# S1C31W74 register map
Vendor: Epson; Series: S1C31W74; File version: 1.11
CPU: CM0PLUS r0p1, little endian, MPU, no FPU, VTOR, 2 interrupt priority bits
Registers are 16-bit, read-write, reset 0x0 unless marked. A register's access mark holds for its fields unless they carry their own. Offsets are from the block's base; [hi:lo] are bit positions; {n}, {i} and the like mark numbered series; 'fields as' and 'values as' point back to an identical list.

## T16B_0 — 16-bit PWM timer channel 0 comparator/capture control
Base 0x40000400
Same registers: T16B_1 0x40000440
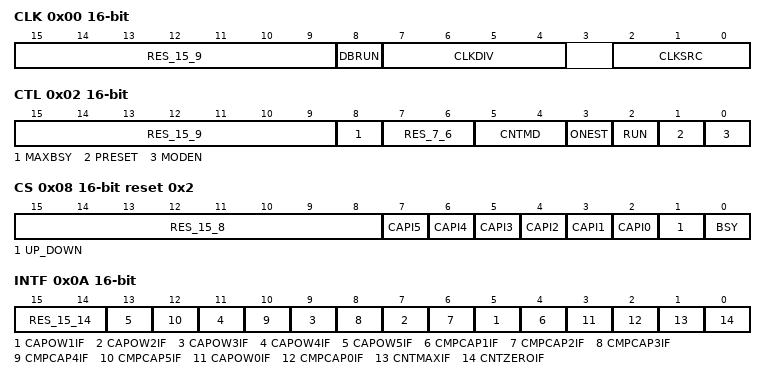
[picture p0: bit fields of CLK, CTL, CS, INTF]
0x00 CLK — Clock Control Register
  [15:9] RES_15_9 ro — Reserved bits
  [8] DBRUN — Enable clock on debug mode
    0=DISABLE; 1=ENABLE
  [7:4] CLKDIV — Clock division select
  [2:0] CLKSRC — Clock source select
    0=IOSC; 1=OSC1; 2=OSC3; 3=EXOSC; 4=EXCLN0; 5=EXCLN1; 6=EXCLN0_INV (EXCLn0 Invert); 7=EXCLN1_INV (EXCLn1 Invert)
0x02 CTL — Counter Control Register
  [15:9] RES_15_9 ro — Reserved bits
  [8] MAXBSY — Max register busy flag
    0=IDLE (Idle (can be written)); 1=BUSY (Busy status (cannot be written))
  [7:6] RES_7_6 ro — Reserved bits
  [5:4] CNTMD — Count mode select
    0=UP (Up count mode); 1=DOWN (Down count mode); 2=UP_DOWN (Up/down count mode)
  [3] ONEST — One shot mode
    0=REPEAT (Repeat mode); 1=ONESHOT (One-shot mode)
  [2] RUN — Count mode select
    0=STOP (Repeat mode); 1=RUN (One-shot mode)
  [1] PRESET write-1-sets — Counter preset (reset)
    on write: 0=NON (No effect); 1=ISSUE (Issue a preset (reset)) | on read: 0=COMPLETED (Resetting finished or normal operation); 1=IN_PROGRESS (Resetting in progress)
  [0] MODEN — T16B enable
    0=DISABLE (Disable (Stop supplying operating clock)); 1=ENABLE (Enable (Start supplying operating clock))
0x04 MC reset 0xFFFF — MAX Counter Data Register
  [15:0] MC — Max Counter Value
0x06 TC ro — Timer Counter Data Register
  [15:0] TC — Counter data
0x08 CS ro reset 0x2 — Counter Status Register
  [15:8] RES_15_8 — Reserved bits
  [7] CAPI5 — Capture5 input status
    0=LOW (Input signal = Low level); 1=HIGH (Input signal = High level)
  [6] CAPI4 — Capture1 input status
    values as CAPI5
  [n+2] CAPI{n} (n=0..3) — Capture{n} input status
    values as CAPI5
  [1] UP_DOWN — Counter UP/DOWN status
    0=DOWN (Count down); 1=UP (Count up)
  [0] BSY — Counter Run Status
    0=STOP (Idle); 1=RUN (Running)
0x0A INTF — Compare/Capture Interrupt Flag Register
  [15:14] RES_15_14 ro — Reserved bits
  [2n+3] CAPOW{n}IF ro write-1-clears (n=1..5) — Capture over write interrupt flag 1
    0=NOT_OCCURED (No cause of interrupt occurred); 1=OCCURED (Cause of interrupt occurred)
  [2n+2] CMPCAP{n}IF ro write-1-clears (n=1..5) — Compare/Capture interrupt flag 1
    values as CAPOW1IF
  [3] CAPOW0IF ro write-1-clears — Capture over write interrupt flag 0
    values as CAPOW1IF
  [2] CMPCAP0IF ro write-1-clears — Compare/Capture interrupt flag 0
    values as CAPOW1IF
  [1] CNTMAXIF ro write-1-clears — Counter Max interrupt flag
    values as CAPOW1IF
  [0] CNTZEROIF ro write-1-clears — Counter 0 interrupt flag
    values as CAPOW1IF
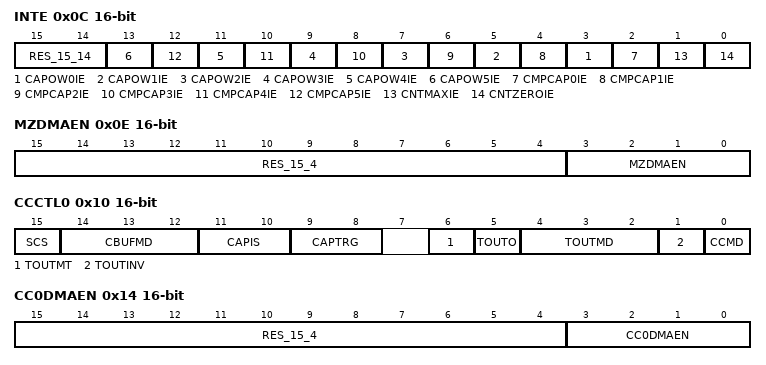
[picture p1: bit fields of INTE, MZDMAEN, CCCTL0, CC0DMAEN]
0x0C INTE — T16B Interrupt Enable Register
  [15:14] RES_15_14 ro — Reserved bits
  [2n+3] CAPOW{n}IE (n=0..5) — Capture over write interrupt enable {n}
    0=DISABLE; 1=ENABLE
  [2n+2] CMPCAP{n}IE (n=0..5) — Compare/Capture interrupt enable {n}
    0=DISABLE; 1=ENABLE
  [1] CNTMAXIE — Counter Max interrupt enable
    0=DISABLE; 1=ENABLE
  [0] CNTZEROIE — Counter 0 interrupt enable
    0=DISABLE; 1=ENABLE
0x0E MZDMAEN — MZ DMA Enable Register
  [15:4] RES_15_4 ro — Reserved bits
  [3:0] MZDMAEN — Max/Zero DMA request enable
0x10 CCCTL0 — Compare/Capture0 Control Register
  [15] SCS — SCS register mode select
    0=ASYNC (Asynchronous capture mode); 1=SYNC (Synchronous capture mode)
  [14:12] CBUFMD — Compare buffer mode select
    0=NONE; 1=PERIOD; 2=COMPARE; 3=EXCEPT; 4=CLEAR
  [11:10] CAPIS — Capture input signal select
    0=CCI; 2=0_INPUT; 3=1_INPUT
  [9:8] CAPTRG — Capture trigger select
    0=NONE; 1=RISING (Rising edge); 2=FALLING (Falling edge); 3=BOTH (Rising or falling edge)
  [6] TOUTMT — Tout Motor mode select
    0=NORMAL; 1=MT
  [5] TOUTO — Tout Output select
    0=LOW; 1=HIGH
  [4:2] TOUTMD — Tout Output mode select
    0=TOUTOX (Software control mode); 1=SET (Set mode); 2=TOGGLE_SET (Toggle set mode); 3=SET_TOGGLE (Set/toggle mode); 4=TOGGLE (Toggle mode); 5=RESET (Reset mode); 6=TOGGLE_SET (Toggle/set mode); 7=RESET_SET (Reset/set mode)
  [1] TOUTINV — Tout invert
    0=NORMAL (Normal (active high)); 1=INVERT (Inverted (active low))
  [0] CCMD — T16B CCA register mode select
    0=COMP (Comparator mode (T16nCCRm register = compare data register)); 1=CAPT (Capture mode (T16nCCRm register = capture register))
0x12 CCR0 reset 0xFFFF — Compare/Capture0 Data Register
  [15:0] CC — Compare/Capture data
0x14 CC0DMAEN — CC0 DMA Enable Register
  [15:4] RES_15_4 ro — Reserved bits
  [3:0] CC0DMAEN — Compare/Capture0 DMA ch3 request enable
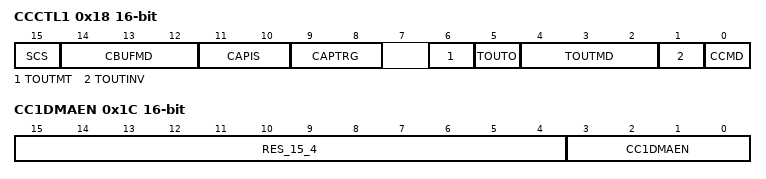
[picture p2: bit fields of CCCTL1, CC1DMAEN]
0x18 CCCTL1 — Compare/Capture1 Control Register
  fields as CCCTL0
0x1A CCR1 reset 0xFFFF — Compare/Capture1 Data Register
  [15:0] CC — Compare/Capture data
0x1C CC1DMAEN — CC1 DMA Enable Register
  [15:4] RES_15_4 ro — Reserved bits
  [3:0] CC1DMAEN — Compare/Capture1 DMA ch3 request enable
